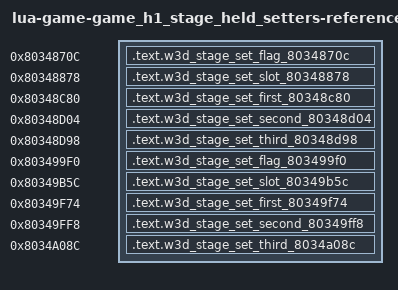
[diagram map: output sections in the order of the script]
/* Generated reference-only placements. All bodies are source-built. */
OUTPUT_FORMAT("elf32-powerpc")
OUTPUT_ARCH(powerpc)
ENTRY(w3d_stage_set_flag_8034870c)
_SDA_BASE_ = 0x804b2540;
_SDA2_BASE_ = 0x804c2540;
SECTIONS {
  .text.w3d_stage_set_flag_8034870c 0x8034870c : { *(.text.w3d_stage_set_flag_8034870c) }
  .text.w3d_stage_set_slot_80348878 0x80348878 : { *(.text.w3d_stage_set_slot_80348878) }
  .text.w3d_stage_set_first_80348c80 0x80348c80 : { *(.text.w3d_stage_set_first_80348c80) }
  .text.w3d_stage_set_second_80348d04 0x80348d04 : { *(.text.w3d_stage_set_second_80348d04) }
  .text.w3d_stage_set_third_80348d98 0x80348d98 : { *(.text.w3d_stage_set_third_80348d98) }
  .text.w3d_stage_set_flag_803499f0 0x803499f0 : { *(.text.w3d_stage_set_flag_803499f0) }
  .text.w3d_stage_set_slot_80349b5c 0x80349b5c : { *(.text.w3d_stage_set_slot_80349b5c) }
  .text.w3d_stage_set_first_80349f74 0x80349f74 : { *(.text.w3d_stage_set_first_80349f74) }
  .text.w3d_stage_set_second_80349ff8 0x80349ff8 : { *(.text.w3d_stage_set_second_80349ff8) }
  .text.w3d_stage_set_third_8034a08c 0x8034a08c : { *(.text.w3d_stage_set_third_8034a08c) }
  /DISCARD/ : { *(.text*) *(.rodata*) *(.data*) *(.bss*) *(.sdata*) *(.sbss*) *(.comment) }
}
